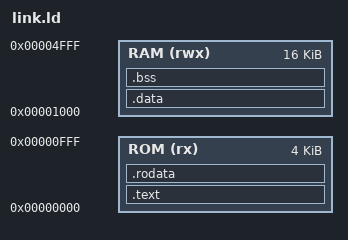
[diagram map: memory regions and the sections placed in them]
ENTRY(_start)

MEMORY
{
    ROM (rx)  : ORIGIN = 0x00000000, LENGTH = 4K
    RAM (rwx) : ORIGIN = 0x00001000, LENGTH = 16K
}

SECTIONS
{
    .text :
    {
        *(.text.start)
        *(.text*)
    } > ROM

    .rodata :
    {
        *(.rodata*)
    } > ROM

    .data :
    {
        *(.data*)
    } > RAM

    .bss :
    {
        *(.bss*)
        *(COMMON)
    } > RAM

    _stack_top = ORIGIN(RAM) + LENGTH(RAM);
}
